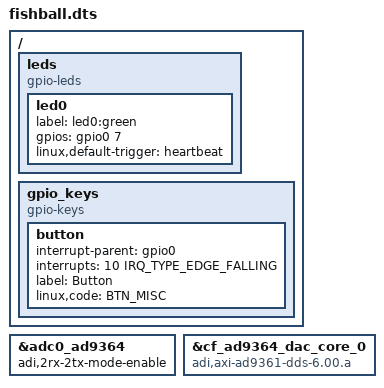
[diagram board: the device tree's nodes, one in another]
// SPDX-License-Identifier: GPL-2.0
/*
 * Analog Devices ADALM Pluto
 * https://wiki.analog.com/university/tools/pluto
 * https://wiki.analog.com/university/tools/pluto/users
 * https://wiki.analog.com/university/tools/pluto/users/firmware
 * https://wiki.analog.com/university/tools/pluto/other
 *
 * hdl_project: <pluto>
 * board_revision: <A>
 *
 * Copyright (C) 2016-2019 Analog Devices Inc.
 */
/dts-v1/;
#include "fishball.dtsi"


&adc0_ad9364 {
	// This property is controlled by u-boot environment.
	adi,2rx-2tx-mode-enable;
};

&cf_ad9364_dac_core_0 {
	/* This property is controlled by u-boot environment. */
	compatible = "adi,axi-ad9361-dds-6.00.a";
};

/ {
	leds {
		compatible = "gpio-leds";
		led0 {
			label = "led0:green";
			gpios = <&gpio0 7 0>;
			linux,default-trigger = "heartbeat";
		};
		/* The JP5 header lines (EMIO, gpio0 54 + EMIO bit) are not described here:
		 * /usr/bin/extio configures them as named inputs or outputs from the
		 * extio_pinNN settings (config.txt [EXTIO], see /etc/extio.conf). */
	};

	gpio_keys {
		compatible = "gpio-keys";
		#address-cells = <1>;
		#size-cells = <0>;

		button {
			interrupt-parent = <&gpio0>;
			interrupts = <10 IRQ_TYPE_EDGE_FALLING>;
			label = "Button";
			linux,code = <BTN_MISC>;
		};

	};

	
};
